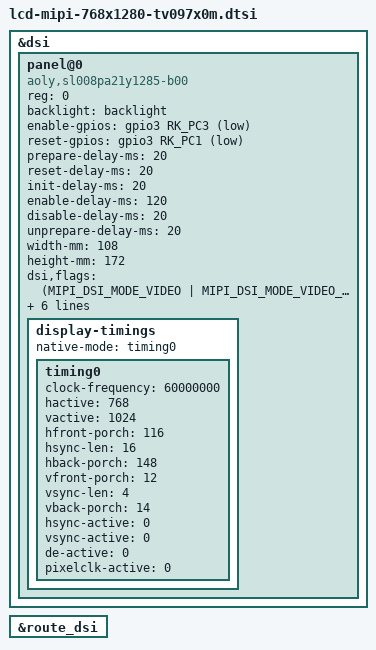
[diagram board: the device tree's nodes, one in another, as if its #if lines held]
&dsi {
	status = "okay";

	panel@0 {
		compatible = "aoly,sl008pa21y1285-b00", "simple-panel-dsi";
		reg = <0>;
		backlight = <&backlight>;
	//	power-supply = <&vcc5v0_host>;//vcc5v0_host  vcc3v3_lcd
	//	power-invert;
#if defined (DHTX_CFP3310M1A)
		enable-gpios = <&gpio3 RK_PC3 GPIO_ACTIVE_LOW>;
#else
		enable-gpios = <&gpio3 RK_PC0 GPIO_ACTIVE_HIGH>;
#endif
		reset-gpios = <&gpio3 RK_PC1 GPIO_ACTIVE_LOW>;
		prepare-delay-ms = <20>;
		reset-delay-ms = <20>;
		init-delay-ms = <20>;
		enable-delay-ms = <120>;
		disable-delay-ms = <20>;
		unprepare-delay-ms = <20>;

		width-mm = <108>;
		height-mm = <172>;

		dsi,flags = <(MIPI_DSI_MODE_VIDEO | MIPI_DSI_MODE_VIDEO_BURST |
			      MIPI_DSI_MODE_LPM | MIPI_DSI_MODE_EOT_PACKET)>;
		dsi,format = <MIPI_DSI_FMT_RGB888>;
		dsi,lanes = <4>;

		panel-init-sequence = [

39 00 03 f0 5a 5a
39 00 03 f1 5a 5a
39 00 03 fc a5 a5
39 00 03 d0 00 10
39 00 04 d8 5d b8 10
05 78 01 11
05 14 01 29
//--- TE----//
15 00 02   35  00 

		];

		panel-exit-sequence = [
			05 00 01 28
			05 00 01 10
		];

		display-timings {
			native-mode = <&timing0>;

			timing0: timing0 {
				clock-frequency = <60000000>;
				hactive = <768>;
				vactive = <1024>;//1068
				hfront-porch = <116>;
				hsync-len = <16>;
				hback-porch = <148>;
				vfront-porch = <12>;//124
				vsync-len = <4>;
				vback-porch = <14>;//116
				hsync-active = <0>;
				vsync-active = <0>;
				de-active = <0>;
				pixelclk-active = <0>;
			};
		};
	};
};


&route_dsi {
	status = "okay";
};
